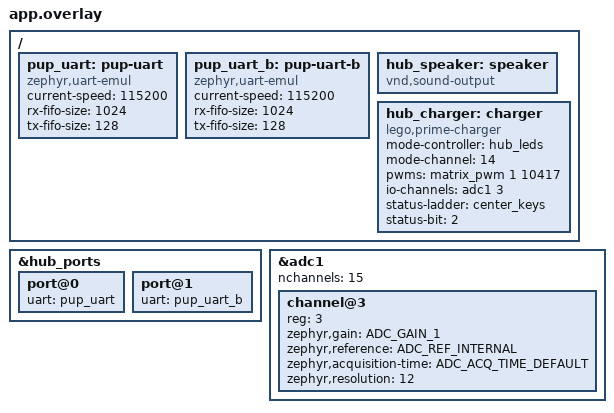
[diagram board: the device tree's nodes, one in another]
/* SPDX-License-Identifier: Apache-2.0 */
#include "../native/battery.dtsi"
#include "../native/lights.dtsi"
#include "../ports/ports.dtsi"
#include "../ports/motor-pwm.dtsi"
/ {
	pup_uart: pup-uart {
		compatible = "zephyr,uart-emul";
		current-speed = <115200>;
		rx-fifo-size = <1024>;
		tx-fifo-size = <128>;
	};
	pup_uart_b: pup-uart-b {
		compatible = "zephyr,uart-emul";
		current-speed = <115200>;
		rx-fifo-size = <1024>;
		tx-fifo-size = <128>;
	};
	hub_speaker: speaker {
		compatible = "vnd,sound-output";
		status = "okay";
	};

};
&hub_ports {
	port@0 { uart = <&pup_uart>; };
	port@1 { uart = <&pup_uart_b>; };
};

#include "storage.overlay"

#include "../../boards/lego/spike_prime_f4/buttons.dtsi"
&adc1 {
	nchannels = <15>;
	channel@3 {
		reg = <3>;
		zephyr,gain = "ADC_GAIN_1";
		zephyr,reference = "ADC_REF_INTERNAL";
		zephyr,acquisition-time = <ADC_ACQ_TIME_DEFAULT>;
		zephyr,resolution = <12>;
	};
};
/ {
	hub_charger: charger {
		compatible = "lego,prime-charger";
		mode-controller = <&hub_leds>;
		mode-channel = <14>;
		pwms = <&matrix_pwm 1 10417>;
		io-channels = <&adc1 3>;
		status-ladder = <&center_keys>;
		status-bit = <2>;
	};
};
